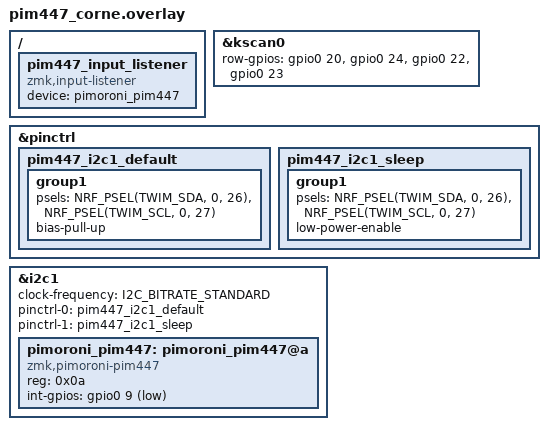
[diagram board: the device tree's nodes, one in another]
/*
 * PIM447 trackball add-on for the right half of a Corne on a nice!nano v2.
 *
 * This layers on top of ZMK's stock `corne_right` shield instead of replacing
 * it, so it must be listed AFTER corne_right in build.yaml. It does three
 * things:
 *
 *   1. re-routes the matrix rows to free pro_micro D6/D7 for the trackball,
 *   2. brings up i2c1 on P0.26 (SDA) / P0.27 (SCL),
 *   3. instantiates the PIM447 and forwards its input events to HID.
 *
 * Driver bindings come from the `pim447` module (t0bybr/pim447) listed in
 * config/west.yml.
 */

/*
 * Instantiates the `pim447` behavior node. Required, not optional:
 * CONFIG_ZMK_PIM447_BEHAVIORS defaults to y whenever the driver is enabled,
 * and behavior_pim447.c calls BEHAVIOR_DT_INST_DEFINE(0, ...) unconditionally,
 * so the build fails to compile if no zmk,behavior-pim447 node exists.
 *
 * Included here rather than in config/corne.keymap because that keymap is
 * shared with the left half, which has no PIM447. A side benefit is that
 * `&pim447 <action>` is now bindable on this half (see
 * dt-bindings/behavior_pim447.h for the actions).
 */
#include <behaviors/behavior_pim447.dtsi>

&kscan0 {
    /*
     * Custom right-hand row wiring. Upstream corne uses pro_micro 4/5/6/7
     * (P0.22, P0.24, P1.00, P0.11); this frees D6 (P1.00) and D7 (P0.11).
     */
    row-gpios
        = <&gpio0 20 (GPIO_ACTIVE_HIGH | GPIO_PULL_DOWN)>
        , <&gpio0 24 (GPIO_ACTIVE_HIGH | GPIO_PULL_DOWN)>
        , <&gpio0 22 (GPIO_ACTIVE_HIGH | GPIO_PULL_DOWN)>
        , <&gpio0 23 (GPIO_ACTIVE_HIGH | GPIO_PULL_DOWN)>
        ;
};

/*
 * Prefixed node labels so these never collide with the pinctrl states the
 * nice!nano board definition already declares.
 */
&pinctrl {
    pim447_i2c1_default: pim447_i2c1_default {
        group1 {
            psels = <NRF_PSEL(TWIM_SDA, 0, 26)>,
                    <NRF_PSEL(TWIM_SCL, 0, 27)>;
            bias-pull-up;
        };
    };

    pim447_i2c1_sleep: pim447_i2c1_sleep {
        group1 {
            psels = <NRF_PSEL(TWIM_SDA, 0, 26)>,
                    <NRF_PSEL(TWIM_SCL, 0, 27)>;
            low-power-enable;
        };
    };
};

&i2c1 {
    status = "okay";
    clock-frequency = <I2C_BITRATE_STANDARD>;
    pinctrl-0 = <&pim447_i2c1_default>;
    pinctrl-1 = <&pim447_i2c1_sleep>;
    pinctrl-names = "default", "sleep";

    pimoroni_pim447: pimoroni_pim447@a {
        compatible = "zmk,pimoroni-pim447";
        reg = <0x0a>;
        int-gpios = <&gpio0 9 (GPIO_ACTIVE_LOW | GPIO_PULL_UP)>;
    };
};

/ {
    /*
     * Required. The driver only reports into Zephyr's input subsystem; without
     * a listener nothing forwards those events to the HID mouse endpoint and
     * the host sees no movement even though the trackball is working.
     */
    pim447_input_listener: pim447_input_listener {
        compatible = "zmk,input-listener";
        device = <&pimoroni_pim447>;
    };
};
